VERSION ""

NS_ :

BS_:

BU_:

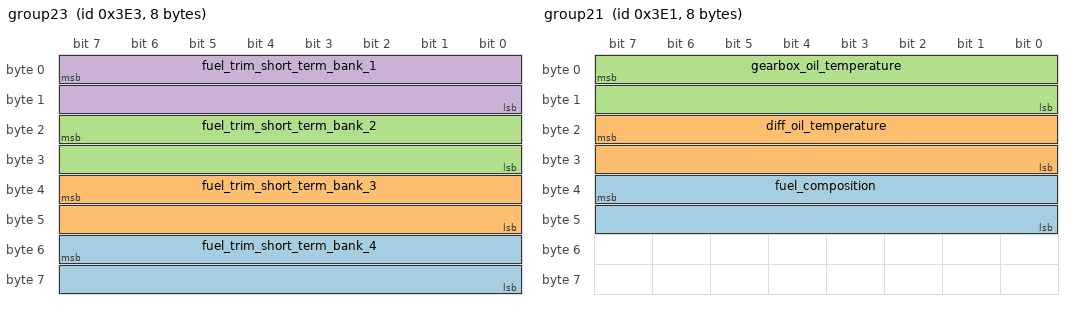
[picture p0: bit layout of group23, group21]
BO_ 995 group23: 8 Vector__XXX
 SG_ fuel_trim_short_term_bank_4 : 55|16@0- (0.1,0) [0|0] "%" Vector__XXX
 SG_ fuel_trim_short_term_bank_3 : 39|16@0- (0.1,0) [0|0] "%" Vector__XXX
 SG_ fuel_trim_short_term_bank_2 : 23|16@0- (0.1,0) [0|0] "%" Vector__XXX
 SG_ fuel_trim_short_term_bank_1 : 7|16@0- (0.1,0) [0|0] "%" Vector__XXX

BO_ 994 group22: 8 Vector__XXX
 SG_ fuel_level : 7|16@0+ (0.1,0) [0|0] "L" Vector__XXX

BO_ 993 group21: 8 Vector__XXX
 SG_ fuel_composition : 39|16@0+ (0.1,0) [0|0] "%" Vector__XXX
 SG_ diff_oil_temperature : 23|16@0+ (0.1,0) [0|0] "K" Vector__XXX
 SG_ gearbox_oil_temperature : 7|16@0+ (0.1,0) [0|0] "K" Vector__XXX

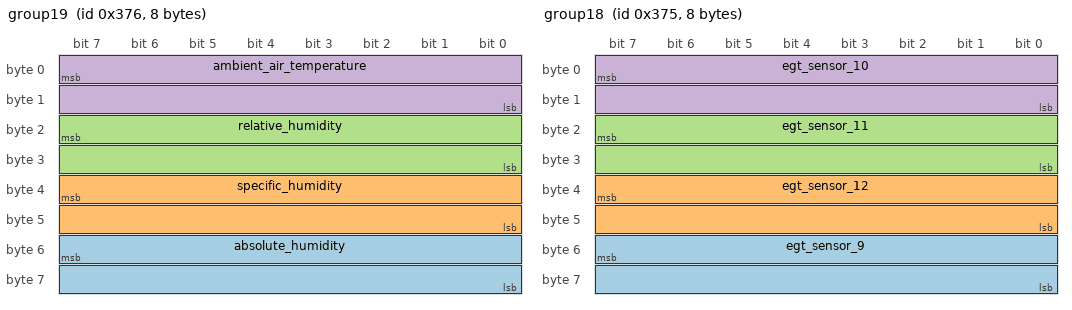
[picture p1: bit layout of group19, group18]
BO_ 886 group19: 8 Vector__XXX
 SG_ absolute_humidity : 55|16@0+ (0.1,0) [0|0] "g/m3" Vector__XXX
 SG_ specific_humidity : 39|16@0+ (100,0) [0|0] "ppm" Vector__XXX
 SG_ relative_humidity : 23|16@0- (0.1,0) [0|0] "%" Vector__XXX
 SG_ ambient_air_temperature : 7|16@0+ (0.1,0) [0|0] "K" Vector__XXX

BO_ 885 group18: 8 Vector__XXX
 SG_ egt_sensor_9 : 55|16@0+ (0.1,0) [0|0] "K" Vector__XXX
 SG_ egt_sensor_12 : 39|16@0+ (0.1,0) [0|0] "K" Vector__XXX
 SG_ egt_sensor_11 : 23|16@0+ (0.1,0) [0|0] "K" Vector__XXX
 SG_ egt_sensor_10 : 7|16@0+ (0.1,0) [0|0] "K" Vector__XXX

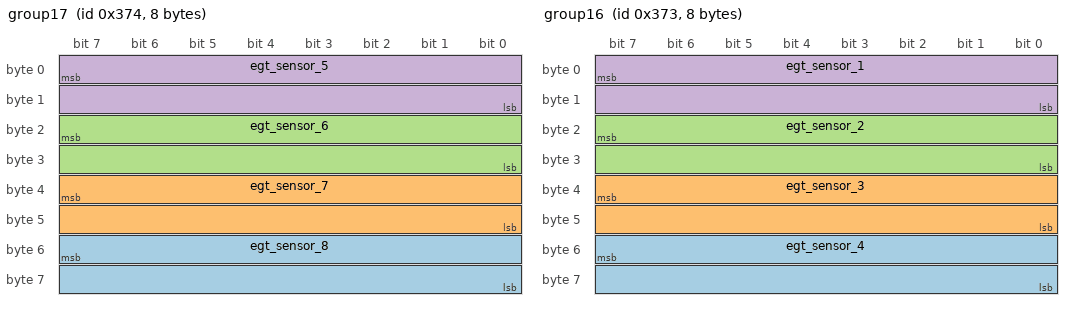
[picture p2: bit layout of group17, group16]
BO_ 884 group17: 8 Vector__XXX
 SG_ egt_sensor_8 : 55|16@0+ (0.1,0) [0|0] "K" Vector__XXX
 SG_ egt_sensor_7 : 39|16@0+ (0.1,0) [0|0] "K" Vector__XXX
 SG_ egt_sensor_6 : 23|16@0+ (0.1,0) [0|0] "K" Vector__XXX
 SG_ egt_sensor_5 : 7|16@0+ (0.1,0) [0|0] "K" Vector__XXX

BO_ 883 group16: 8 Vector__XXX
 SG_ egt_sensor_4 : 55|16@0+ (0.1,0) [0|0] "K" Vector__XXX
 SG_ egt_sensor_3 : 39|16@0+ (0.1,0) [0|0] "K" Vector__XXX
 SG_ egt_sensor_2 : 23|16@0+ (0.1,0) [0|0] "K" Vector__XXX
 SG_ egt_sensor_1 : 7|16@0+ (0.1,0) [0|0] "K" Vector__XXX

BO_ 881 group14: 8 Vector__XXX
 SG_ fuel_flow_return : 23|16@0+ (1,0) [0|0] "cc/min" Vector__XXX
 SG_ fuel_flow : 7|16@0+ (1,0) [0|0] "cc/min" Vector__XXX

BO_ 879 group12: 8 Vector__XXX
 SG_ boost_control_output : 23|16@0+ (1,0) [0|0] "%" Vector__XXX
 SG_ generic_output_1_duty_cycle : 7|16@0+ (0.1,0) [0|0] "%" Vector__XXX

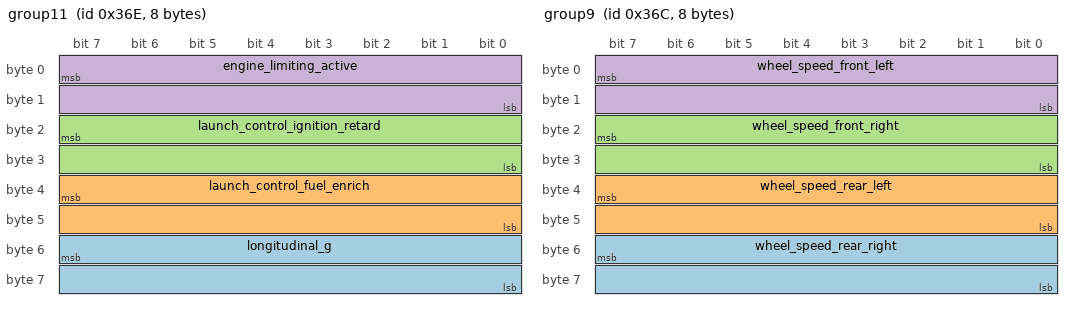
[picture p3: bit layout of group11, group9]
BO_ 878 group11: 8 Vector__XXX
 SG_ longitudinal_g : 55|16@0- (0.1,0) [0|0] "m/s2" Vector__XXX
 SG_ launch_control_fuel_enrich : 39|16@0- (0.1,0) [0|0] "%" Vector__XXX
 SG_ launch_control_ignition_retard : 23|16@0- (0.1,0) [0|0] "°" Vector__XXX
 SG_ engine_limiting_active : 7|16@0+ (1,0) [0|0] "boolean" Vector__XXX

BO_ 877 group10: 8 Vector__XXX
 SG_ exhaust_cam_angle_2 : 55|16@0- (0.1,0) [0|0] "°" Vector__XXX
 SG_ exhaust_cam_angle_1 : 39|16@0- (0.1,0) [0|0] "°" Vector__XXX

BO_ 876 group9: 8 Vector__XXX
 SG_ wheel_speed_rear_right : 55|16@0+ (0.1,0) [0|0] "km/h" Vector__XXX
 SG_ wheel_speed_rear_left : 39|16@0+ (0.1,0) [0|0] "km/h" Vector__XXX
 SG_ wheel_speed_front_right : 23|16@0+ (0.1,0) [0|0] "km/h" Vector__XXX
 SG_ wheel_speed_front_left : 7|16@0+ (0.1,0) [0|0] "km/h" Vector__XXX

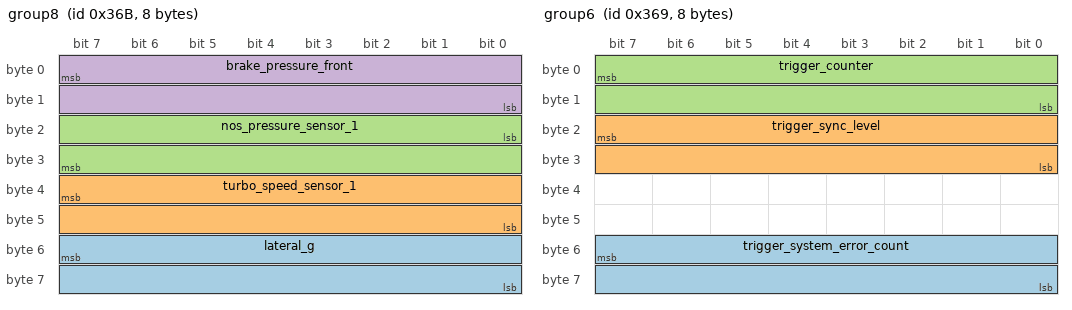
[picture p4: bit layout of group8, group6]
BO_ 875 group8: 8 Vector__XXX
 SG_ lateral_g : 55|16@0- (0.1,0) [0|0] "m/s2" Vector__XXX
 SG_ turbo_speed_sensor_1 : 39|16@0+ (10,0) [0|0] "RPM" Vector__XXX
 SG_ nos_pressure_sensor_1 : 16|16@1+ (0.22,-101.3) [0|0] "kPa" Vector__XXX
 SG_ brake_pressure_front : 7|16@0+ (1,-101.3) [0|0] "kPa" Vector__XXX

BO_ 873 group6: 8 Vector__XXX
 SG_ trigger_system_error_count : 55|16@0+ (1,0) [0|0] "raw" Vector__XXX
 SG_ trigger_sync_level : 23|16@0+ (1,0) [0|0] "raw" Vector__XXX
 SG_ trigger_counter : 7|16@0+ (1,0) [0|0] "raw" Vector__XXX

BO_ 874 group7: 8 Vector__XXX
 SG_ knock_level_2 : 23|16@0+ (0.01,0) [0|0] "dB" Vector__XXX
 SG_ knock_level_1 : 7|16@0+ (0.01,0) [0|0] "dB" Vector__XXX

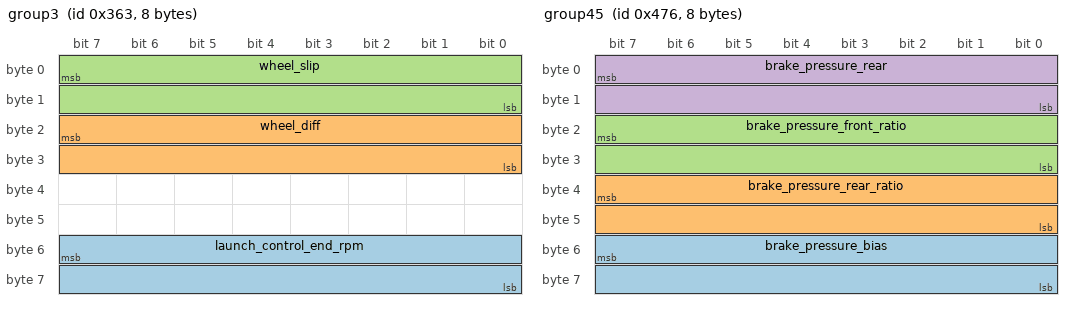
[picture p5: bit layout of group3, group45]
BO_ 867 group3: 8 Vector__XXX
 SG_ launch_control_end_rpm : 55|16@0+ (1,0) [0|0] "RPM" Vector__XXX
 SG_ wheel_diff : 23|16@0- (0.1,0) [0|0] "km/h" Vector__XXX
 SG_ wheel_slip : 7|16@0- (0.1,0) [0|0] "km/h" Vector__XXX

BO_ 1142 group45: 8 Vector__XXX
 SG_ brake_pressure_bias : 55|16@0- (1,0) [0|0] "kPa (Abs)" Vector__XXX
 SG_ brake_pressure_rear_ratio : 39|16@0+ (0.1,0) [0|0] "%" Vector__XXX
 SG_ brake_pressure_front_ratio : 23|16@0+ (0.1,0) [0|0] "%" Vector__XXX
 SG_ brake_pressure_rear : 7|16@0+ (1,-101.3) [0|0] "kPa" Vector__XXX

BO_ 1782 group52: 8 Vector__XXX
 SG_ trip_meter_1 : 39|32@0- (1,0) [0|0] "m" Vector__XXX
 SG_ total_fuel_used_since_trip : 7|32@0- (1,0) [0|0] "cc" Vector__XXX

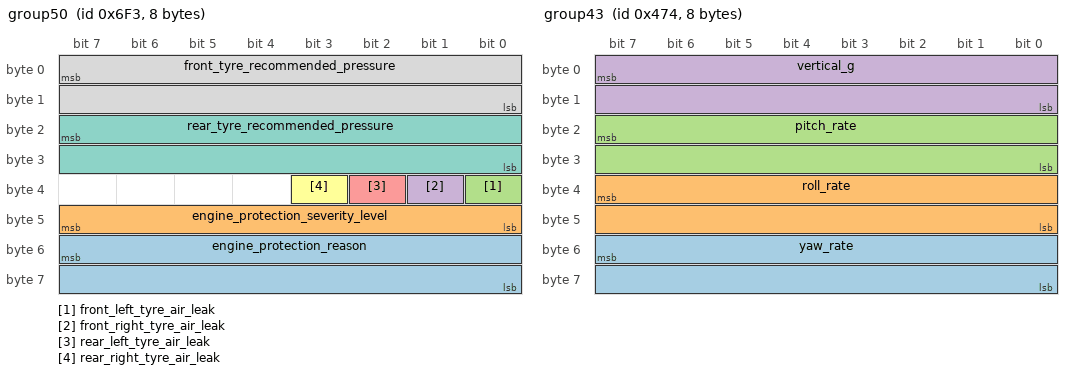
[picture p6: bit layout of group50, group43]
BO_ 1779 group50: 8 Vector__XXX
 SG_ engine_protection_reason : 55|16@0+ (1,0) [0|0] "raw" Vector__XXX
 SG_ engine_protection_severity_level : 47|8@0+ (1,0) [0|0] "raw" Vector__XXX
 SG_ front_left_tyre_air_leak : 32|1@0+ (1,0) [0|0] "boolean" Vector__XXX
 SG_ front_right_tyre_air_leak : 33|1@0+ (1,0) [0|0] "boolean" Vector__XXX
 SG_ rear_left_tyre_air_leak : 34|1@0+ (1,0) [0|0] "boolean" Vector__XXX
 SG_ rear_right_tyre_air_leak : 35|1@0+ (1,0) [0|0] "boolean" Vector__XXX
 SG_ rear_tyre_recommended_pressure : 23|16@0+ (0.1,-101.3) [0|0] "kPa" Vector__XXX
 SG_ front_tyre_recommended_pressure : 7|16@0+ (0.1,-101.3) [0|0] "kPa" Vector__XXX

BO_ 1140 group43: 8 Vector__XXX
 SG_ yaw_rate : 55|16@0- (0.1,0) [0|0] "deg/s" Vector__XXX
 SG_ roll_rate : 39|16@0- (0.1,0) [0|0] "deg/s" Vector__XXX
 SG_ pitch_rate : 23|16@0- (0.1,0) [0|0] "deg/s" Vector__XXX
 SG_ vertical_g : 7|16@0- (0.1,0) [0|0] "m/s2" Vector__XXX

BO_ 1139 group42: 8 Vector__XXX
 SG_ traction_control_switch_state : 36|1@0- (1,0) [0|0] "boolean" Vector__XXX
 SG_ total_fuel_used : 7|32@0+ (1,0) [0|0] "cc" Vector__XXX

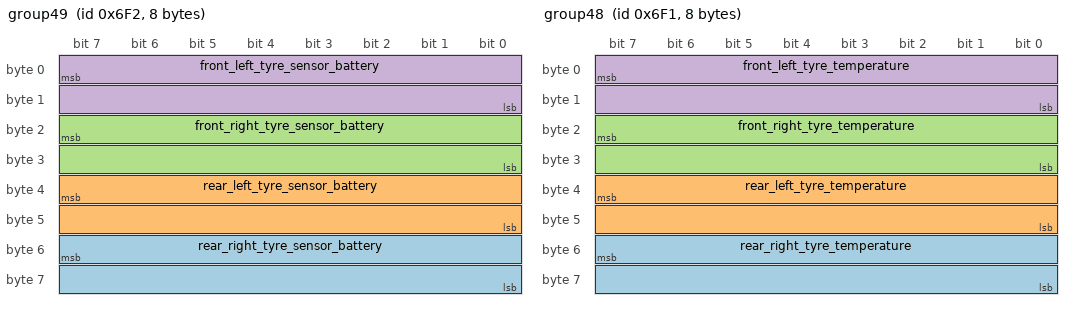
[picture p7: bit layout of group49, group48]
BO_ 1778 group49: 8 Vector__XXX
 SG_ rear_right_tyre_sensor_battery : 55|16@0+ (0.001,0) [0|0] "V" Vector__XXX
 SG_ rear_left_tyre_sensor_battery : 39|16@0+ (0.001,0) [0|0] "V" Vector__XXX
 SG_ front_right_tyre_sensor_battery : 23|16@0+ (0.001,0) [0|0] "V" Vector__XXX
 SG_ front_left_tyre_sensor_battery : 7|16@0+ (0.001,0) [0|0] "V" Vector__XXX

BO_ 1777 group48: 8 Vector__XXX
 SG_ rear_right_tyre_temperature : 55|16@0+ (0.1,0) [0|0] "K" Vector__XXX
 SG_ rear_left_tyre_temperature : 39|16@0+ (0.1,0) [0|0] "K" Vector__XXX
 SG_ front_right_tyre_temperature : 23|16@0+ (0.1,0) [0|0] "K" Vector__XXX
 SG_ front_left_tyre_temperature : 7|16@0+ (0.1,0) [0|0] "K" Vector__XXX

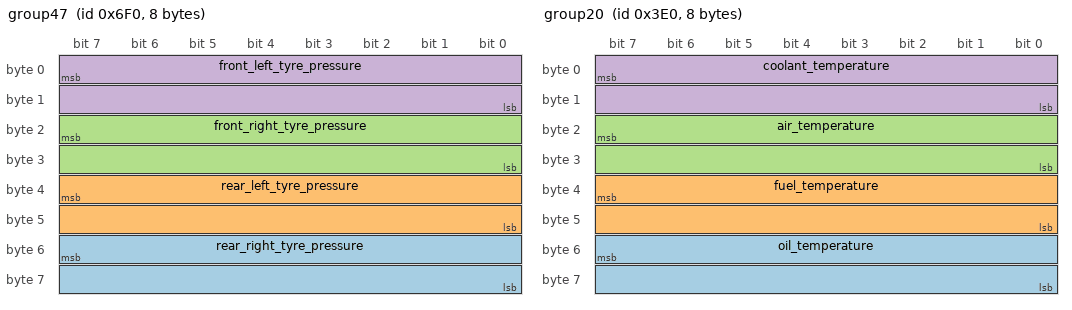
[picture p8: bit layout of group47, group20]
BO_ 1776 group47: 8 Vector__XXX
 SG_ rear_right_tyre_pressure : 55|16@0+ (0.1,-101.3) [0|0] "kPa" Vector__XXX
 SG_ rear_left_tyre_pressure : 39|16@0+ (0.1,-101.3) [0|0] "kPa" Vector__XXX
 SG_ front_right_tyre_pressure : 23|16@0+ (0.1,-101.3) [0|0] "kPa" Vector__XXX
 SG_ front_left_tyre_pressure : 7|16@0+ (0.1,-101.3) [0|0] "kPa" Vector__XXX

BO_ 1137 group40: 8 Vector__XXX
 SG_ accelerator_pedal_position : 23|16@0+ (0.1,0) [0|0] "%" Vector__XXX

BO_ 992 group20: 8 Vector__XXX
 SG_ oil_temperature : 55|16@0+ (0.1,0) [0|0] "K" Vector__XXX
 SG_ fuel_temperature : 39|16@0+ (0.1,0) [0|0] "K" Vector__XXX
 SG_ air_temperature : 23|16@0+ (0.1,0) [0|0] "K" Vector__XXX
 SG_ coolant_temperature : 7|16@0+ (0.1,0) [0|0] "K" Vector__XXX

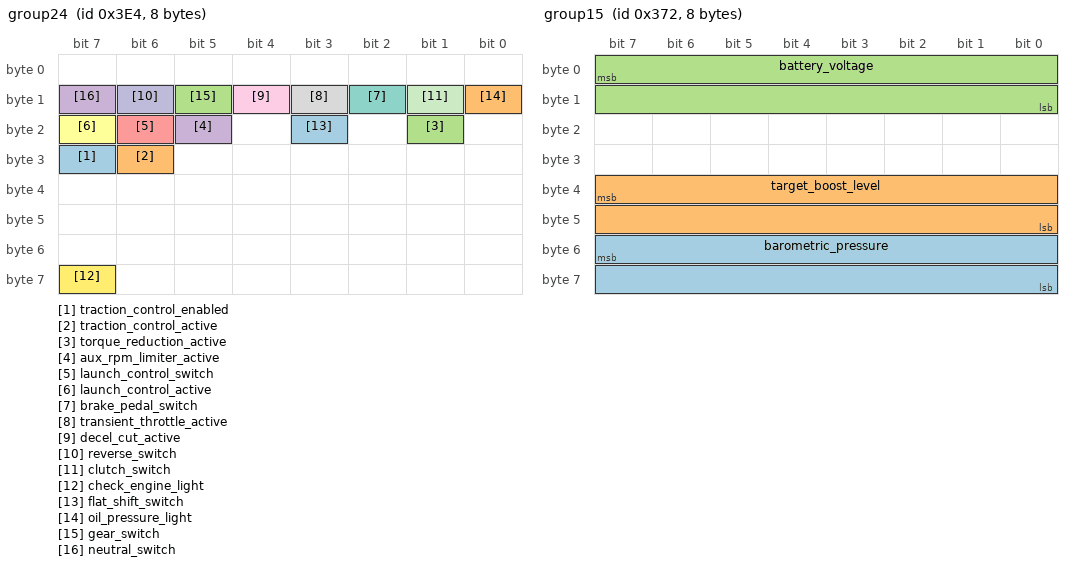
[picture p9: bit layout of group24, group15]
BO_ 996 group24: 8 Vector__XXX
 SG_ traction_control_enabled : 31|1@0+ (1,0) [0|0] "boolean" Vector__XXX
 SG_ traction_control_active : 30|1@0+ (1,0) [0|0] "boolean" Vector__XXX
 SG_ torque_reduction_active : 17|1@0+ (1,0) [0|0] "boolean" Vector__XXX
 SG_ aux_rpm_limiter_active : 21|1@0+ (1,0) [0|0] "boolean" Vector__XXX
 SG_ launch_control_switch : 22|1@0+ (1,0) [0|0] "boolean" Vector__XXX
 SG_ launch_control_active : 23|1@0+ (1,0) [0|0] "boolean" Vector__XXX
 SG_ brake_pedal_switch : 10|1@0+ (1,0) [0|0] "boolean" Vector__XXX
 SG_ transient_throttle_active : 11|1@0+ (1,0) [0|0] "boolean" Vector__XXX
 SG_ decel_cut_active : 12|1@0+ (1,0) [0|0] "boolean" Vector__XXX
 SG_ reverse_switch : 14|1@0+ (1,0) [0|0] "boolean" Vector__XXX
 SG_ clutch_switch : 9|1@0+ (1,0) [0|0] "" Vector__XXX
 SG_ check_engine_light : 63|1@0+ (1,0) [0|0] "" Vector__XXX
 SG_ flat_shift_switch : 19|1@0+ (1,0) [0|0] "" Vector__XXX
 SG_ oil_pressure_light : 8|1@0+ (1,0) [0|0] "" Vector__XXX
 SG_ gear_switch : 13|1@0+ (1,0) [0|0] "" Vector__XXX
 SG_ neutral_switch : 15|1@0+ (1,0) [0|0] "boolean" Vector__XXX

BO_ 882 group15: 8 Vector__XXX
 SG_ barometric_pressure : 55|16@0+ (0.1,0) [0|0] "kPa (Abs)" Vector__XXX
 SG_ target_boost_level : 39|16@0+ (0.1,0) [0|0] "kPa" Vector__XXX
 SG_ battery_voltage : 7|16@0+ (0.1,0) [0|0] "Volts" Vector__XXX

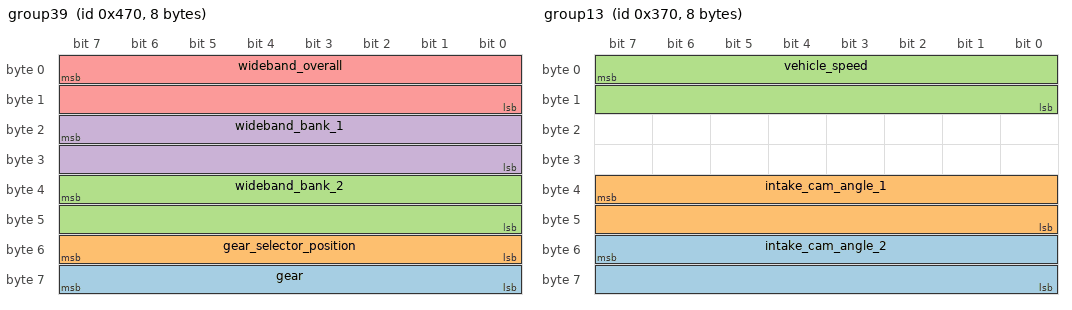
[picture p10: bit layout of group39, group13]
BO_ 1136 group39: 8 Vector__XXX
 SG_ gear : 63|8@0- (1,0) [0|0] "" Vector__XXX
 SG_ gear_selector_position : 55|8@0- (1,0) [0|0] "" Vector__XXX
 SG_ wideband_bank_2 : 39|16@0+ (0.001,0) [0|0] "Lambda" Vector__XXX
 SG_ wideband_bank_1 : 23|16@0+ (0.001,0) [0|0] "Lambda" Vector__XXX
 SG_ wideband_overall : 7|16@0+ (0.001,0) [0|0] "Lambda" Vector__XXX

BO_ 880 group13: 8 Vector__XXX
 SG_ intake_cam_angle_2 : 55|16@0- (0.1,0) [0|0] "°" Vector__XXX
 SG_ intake_cam_angle_1 : 39|16@0- (0.1,0) [0|0] "°" Vector__XXX
 SG_ vehicle_speed : 7|16@0+ (0.1,0) [0|0] "km/h" Vector__XXX

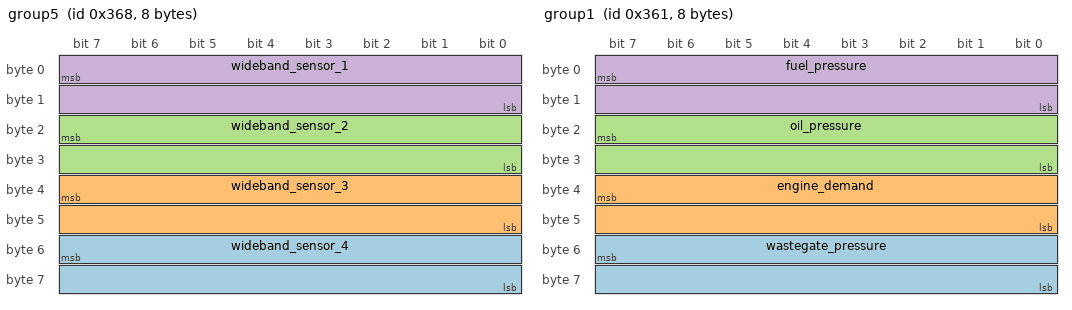
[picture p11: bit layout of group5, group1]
BO_ 872 group5: 8 Vector__XXX
 SG_ wideband_sensor_4 : 55|16@0+ (0.001,0) [0|0] "Lambda" Vector__XXX
 SG_ wideband_sensor_3 : 39|16@0+ (0.001,0) [0|0] "Lambda" Vector__XXX
 SG_ wideband_sensor_2 : 23|16@0+ (0.001,0) [0|0] "Lambda" Vector__XXX
 SG_ wideband_sensor_1 : 7|16@0+ (0.001,0) [0|0] "Lambda" Vector__XXX

BO_ 865 group1: 8 Vector__XXX
 SG_ wastegate_pressure : 55|16@0+ (0.1,-101.3) [0|0] "kPa" Vector__XXX
 SG_ engine_demand : 39|16@0+ (0.1,0) [0|0] "%" Vector__XXX
 SG_ oil_pressure : 23|16@0+ (0.1,-101.3) [0|0] "kPa" Vector__XXX
 SG_ fuel_pressure : 7|16@0+ (0.1,-101.3) [0|0] "kPa" Vector__XXX

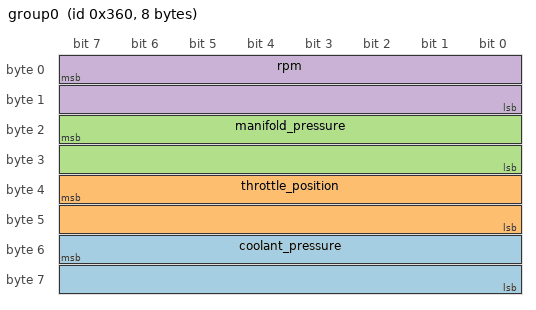
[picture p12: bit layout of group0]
BO_ 864 group0: 8 Vector__XXX
 SG_ coolant_pressure : 55|16@0+ (0.1,-101.3) [0|0] "kPa" Vector__XXX
 SG_ throttle_position : 39|16@0+ (0.1,0) [0|0] "%" Vector__XXX
 SG_ manifold_pressure : 23|16@0+ (0.1,0) [0|0] "kPa (Abs)" Vector__XXX
 SG_ rpm : 7|16@0+ (1,0) [0|0] "RPM" Vector__XXX

CM_ SG_ 1142 brake_pressure_bias "Front-Rear";
CM_ SG_ 992 oil_temperature "20-04";
CM_ SG_ 992 fuel_temperature "20-03";
CM_ SG_ 992 air_temperature "20-02";
CM_ SG_ 992 coolant_temperature "20-01";
CM_ SG_ 996 brake_pedal_switch "24-01";
CM_ SG_ 996 transient_throttle_active "24-01";
CM_ SG_ 996 decel_cut_active "24-01";
CM_ SG_ 996 clutch_switch "24-07";
CM_ SG_ 996 check_engine_light "24-25";
CM_ SG_ 996 flat_shift_switch "24-12";
CM_ SG_ 996 oil_pressure_light "24-08";
CM_ SG_ 996 gear_switch "24-03";
CM_ SG_ 996 neutral_switch "24-01";
CM_ SG_ 882 barometric_pressure "15-03";
CM_ SG_ 882 target_boost_level "15-02";
CM_ SG_ 882 battery_voltage "15-01";
CM_ SG_ 1136 gear "39-05";
CM_ SG_ 1136 gear_selector_position "39-04";
CM_ SG_ 1136 wideband_bank_2 "39-03";
CM_ SG_ 1136 wideband_bank_1 "39-02";
CM_ SG_ 1136 wideband_overall "39-01";
CM_ SG_ 880 intake_cam_angle_2 "13-03";
CM_ SG_ 880 intake_cam_angle_1 "13-02";
CM_ SG_ 880 vehicle_speed "13-01";
CM_ SG_ 872 wideband_sensor_4 "05-04";
CM_ SG_ 872 wideband_sensor_3 "05-03";
CM_ SG_ 872 wideband_sensor_2 "05-02";
CM_ SG_ 872 wideband_sensor_1 "05-01";
CM_ SG_ 865 wastegate_pressure "01-04";
CM_ SG_ 865 engine_demand "01-03";
CM_ SG_ 865 oil_pressure "01-02";
CM_ SG_ 865 fuel_pressure "01-01";
CM_ SG_ 864 coolant_pressure "00-04";
CM_ SG_ 864 throttle_position "00-03";
CM_ SG_ 864 manifold_pressure "00-02";
CM_ SG_ 864 rpm "00-01";
BA_DEF_  "BusType" STRING ;
BA_DEF_DEF_  "BusType" "CAN";
